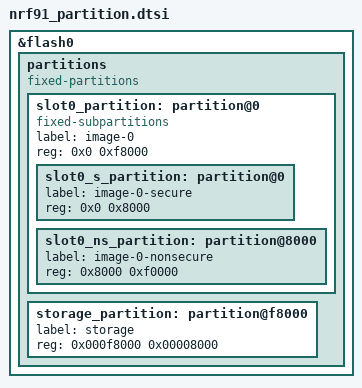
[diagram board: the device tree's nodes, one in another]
/*
 * Copyright (c) 2026 Nordic Semiconductor ASA
 *
 * SPDX-License-Identifier: LicenseRef-Nordic-5-Clause
 */

/delete-node/ &boot_partition;
/delete-node/ &slot0_partition;
/delete-node/ &slot1_partition;
/delete-node/ &tfm_ps_partition;
/delete-node/ &tfm_its_partition;
/delete-node/ &tfm_otp_partition;
/delete-node/ &storage_partition;

&flash0 {
	/*
	 * 0x0000_c000  Primary area                 (992 KB)
	 *   0x0000_c000  Primary secure image         (32 KB)
	 *   0x0001_8000  Primary non-secure image     (960 KB)
	 * 0x000f_e000 Settings storage              (32 KB)
	 */
	partitions {
		compatible = "fixed-partitions";
		#address-cells = <1>;
		#size-cells = <1>;

		slot0_partition: partition@0 {
			compatible = "fixed-subpartitions";
			label = "image-0";
			reg = <0x0 0xf8000>;
			ranges = <0x0 0x0 0xf8000>;
			#address-cells = <1>;
			#size-cells = <1>;

			slot0_s_partition: partition@0 {
				label = "image-0-secure";
				reg = <0x0 0x8000>;
			};

			slot0_ns_partition: partition@8000 {
				label = "image-0-nonsecure";
				reg = <0x8000 0xf0000>;
			};
		};

		storage_partition: partition@f8000 {
			label = "storage";
			reg = <0x000f8000 0x00008000>;
		};
	};
};

/delete-node/ &sram0_s;
/delete-node/ &sram0_ns;

#include <common/nordic/nrf91_partition_sram.dtsi>
